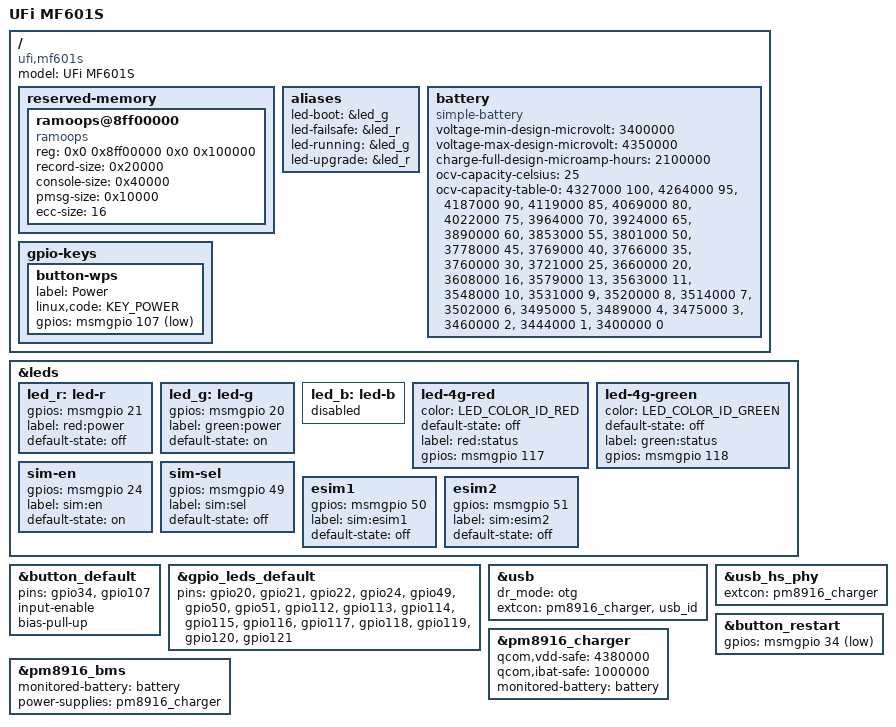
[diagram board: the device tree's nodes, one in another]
// SPDX-License-Identifier: GPL-2.0-only

/dts-v1/;

#include "msm8916-ufi.dtsi"
#include <dt-bindings/input/input.h>

/ {
	model = "UFi MF601S";
	compatible = "ufi,mf601s", "qcom,msm8916";

	reserved-memory {
		#address-cells = <2>;
		#size-cells = <2>;
		ranges;

		ramoops@8ff00000 {
			compatible = "ramoops";
			reg = <0x0 0x8ff00000 0x0 0x100000>; /* 1 MiB */
			record-size = <0x20000>;             /* 128 KiB per oops/panic dump */
			console-size = <0x40000>;            /* 256 KiB live console ring buffer */
			pmsg-size = <0x10000>;               /* 64 KiB userspace log buffer */
			ecc-size = <16>;                     /* 16-byte Reed-Solomon ECC for warm reboots */
		};
	};

	aliases {
		led-boot = &led_g;
		led-failsafe = &led_r;
		led-running = &led_g;
		led-upgrade = &led_r;
	};

	battery: battery {
		compatible = "simple-battery";
		voltage-min-design-microvolt = <3400000>;
		voltage-max-design-microvolt = <4350000>;
		charge-full-design-microamp-hours = <2100000>;

		ocv-capacity-celsius = <25>;
		ocv-capacity-table-0 = < 4327000 100 >,
			< 4264000 95 >,
			< 4187000 90 >,
			< 4119000 85 >,
			< 4069000 80 >,
			< 4022000 75 >,
			< 3964000 70 >,
			< 3924000 65 >,
			< 3890000 60 >,
			< 3853000 55 >,
			< 3801000 50 >,
			< 3778000 45 >,
			< 3769000 40 >,
			< 3766000 35 >,
			< 3760000 30 >,
			< 3721000 25 >,
			< 3660000 20 >,
			< 3608000 16 >,
			< 3579000 13 >,
			< 3563000 11 >,
			< 3548000 10 >,
			< 3531000 9 >,
			< 3520000 8 >,
			< 3514000 7 >,
			< 3502000 6 >,
			< 3495000 5 >,
			< 3489000 4 >,
			< 3475000 3 >,
			< 3460000 2 >,
			< 3444000 1 >,
			< 3400000 0 >;
	};

	gpio-keys {
		button-wps {
			label = "Power";
			linux,code = <KEY_POWER>;
			gpios = <&msmgpio 107 GPIO_ACTIVE_LOW>;
		};
	};
};

&leds {
	led_r: led-r {
		gpios = <&msmgpio 21 GPIO_ACTIVE_HIGH>;
		label = "red:power";
		default-state = "off";
	};

	led_g: led-g {
		gpios = <&msmgpio 20 GPIO_ACTIVE_HIGH>;
		label = "green:power";
		default-state = "on";
	};

	led_b: led-b {
		status = "disabled";
	};

	led-4g-red {
		color = <LED_COLOR_ID_RED>;
		default-state = "off";
		label = "red:status";
		gpios = <&msmgpio 117 GPIO_ACTIVE_HIGH>;
	};

	led-4g-green {
		color = <LED_COLOR_ID_GREEN>;
		default-state = "off";
		label = "green:status";
		gpios = <&msmgpio 118 GPIO_ACTIVE_HIGH>;
	};

	sim-en {
		gpios = <&msmgpio 24 GPIO_ACTIVE_HIGH>;
		label = "sim:en";
		default-state = "on";
	};

	sim-sel {
		gpios = <&msmgpio 49 GPIO_ACTIVE_HIGH>;
		label = "sim:sel";
		default-state = "off";
	};

	esim1 {
		gpios = <&msmgpio 50 GPIO_ACTIVE_HIGH>;
		label = "sim:esim1";
		default-state = "off";
	};

	esim2 {
		gpios = <&msmgpio 51 GPIO_ACTIVE_HIGH>;
		label = "sim:esim2";
		default-state = "off";
	};
};

&button_default {
	pins = "gpio34", "gpio107";
	input-enable;
	bias-pull-up;
};

&gpio_leds_default {
	pins = "gpio20", "gpio21", "gpio22",
	       "gpio24", "gpio49", "gpio50", "gpio51",
	       "gpio112", "gpio113", "gpio114",
	       "gpio115", "gpio116", "gpio117", "gpio118",
	       "gpio119", "gpio120", "gpio121";
};

&usb {
	dr_mode = "otg";
	extcon = <&pm8916_charger>, <&usb_id>;
};

&usb_hs_phy {
	extcon = <&pm8916_charger>;
};

&button_restart {
	gpios = <&msmgpio 34 GPIO_ACTIVE_LOW>;
};

&pm8916_bms {
	status = "okay";

	monitored-battery = <&battery>;
	power-supplies = <&pm8916_charger>;
};

&pm8916_charger {
	status = "okay";

	qcom,vdd-safe = <4380000>;
	qcom,ibat-safe = <1000000>;

	monitored-battery = <&battery>;
};
